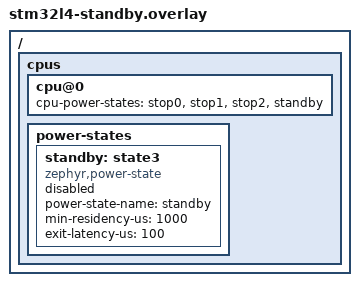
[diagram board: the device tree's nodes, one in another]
/*
 * Copyright (c) 2025 STMicroelectronics
 *
 * SPDX-License-Identifier: Apache-2.0
 */

/ {
	cpus {
		cpu@0 {
			cpu-power-states = <&stop0 &stop1 &stop2 &standby>;
		};

		power-states {
			standby: state3 {
				compatible = "zephyr,power-state";
				power-state-name = "standby";
				min-residency-us = <1000>;
				exit-latency-us = <100>;
				status = "disabled";
			};
		};
	};
};
